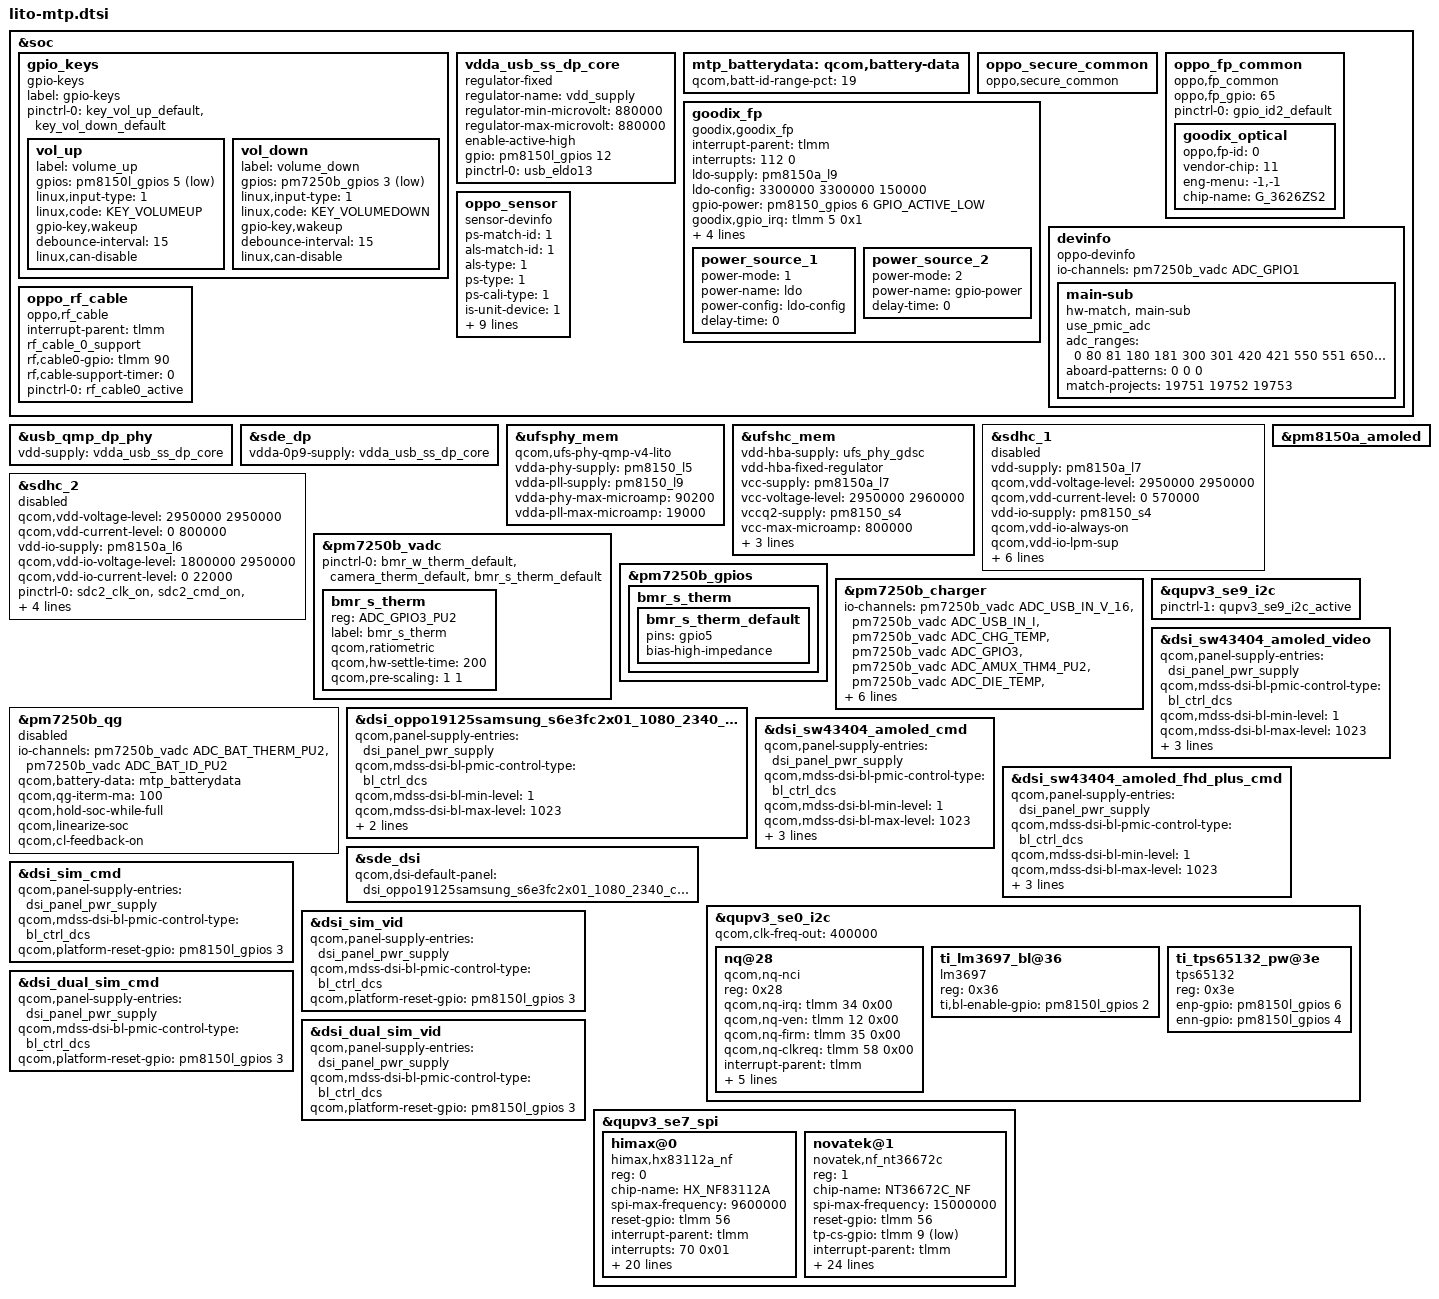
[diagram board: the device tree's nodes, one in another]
#include <dt-bindings/gpio/gpio.h>
#include "lito-audio-overlay.dtsi"
#include "lito-pmic-overlay.dtsi"
#include "camera/lito-camera-sensor-mtp.dtsi"
#include "lito-sde-display.dtsi"
#include "lito-thermal-overlay.dtsi"
#include "oppo_charge.dtsi"

&soc {
	gpio_keys {
		compatible = "gpio-keys";
		label = "gpio-keys";

		pinctrl-names = "default";
		//#ifdef VENDOR_EDIT
		//Fei.Mo@BSP.group 2018-09-01 Modity for vol key
		pinctrl-0 = <&key_vol_up_default &key_vol_down_default>;
		//#endif

		vol_up {
			label = "volume_up";
			gpios = <&pm8150l_gpios 5 GPIO_ACTIVE_LOW>;
			linux,input-type = <1>;
			linux,code = <KEY_VOLUMEUP>;
			gpio-key,wakeup;
			debounce-interval = <15>;
			linux,can-disable;
		};
		//#ifdef VENDOR_EDIT
		//Fei.Mo@BSP.group 2018-09-01 Add for vol key
		vol_down {
			label = "volume_down";
			gpios = <&pm7250b_gpios  3 GPIO_ACTIVE_LOW>;
			linux,input-type = <1>;
			linux,code = <KEY_VOLUMEDOWN>;
			gpio-key,wakeup;
			debounce-interval = <15>;
			linux,can-disable;
		};
		//#endif
	};

	vdda_usb_ss_dp_core: vdda_usb_ss_dp_core {
		compatible = "regulator-fixed";
		regulator-name = "vdd_supply";
		regulator-min-microvolt = <880000>;
		regulator-max-microvolt = <880000>;
		enable-active-high;
		gpio = <&pm8150l_gpios 12 GPIO_ACTIVE_HIGH>;
		pinctrl-names = "default";
		pinctrl-0 = <&usb_eldo13>;
	};

	mtp_batterydata: qcom,battery-data {
//#ifndef VENDOR_EDIT
//Yichun.Chen@BSP.CHG.Basic  2018/05/10  Delete for use oppo battery
//		qcom,batt-id-range-pct = <15>;
//#else
        qcom,batt-id-range-pct = <19>;
//#endif
		#include "qg-batterydata-alium-3600mah.dtsi"
		#include "qg-batterydata-atl466271_3300mAh.dtsi"
	};
	// #ifdef VENDOR_EDIT
	/* Ping.Liu@Bsp.Fingerprint.Secure 2019-10-16 add for secure proc */
	oppo_secure_common {
		compatible = "oppo,secure_common";
	};
	//#endif //VENDOR_EDIT
	//#ifdef VENDOR_EDIT /*VENDOR_EDIT*/
	/*Bangxiong.Wu@BSP.Fingerprint.Basic,2019-04-16 add for fingerprint*/
	oppo_fp_common {
		compatible = "oppo,fp_common";
		oppo,fp_gpio = <65>;
		pinctrl-names = "default";
		pinctrl-0 = <&gpio_id2_default>;
		goodix_optical {
			oppo,fp-id = <0>; /* fp id mapping table */
			vendor-chip = <11>; /* please refer to the struct fp_vendor_t in oppo_fp_commmon.n */
			eng-menu = "-1,-1"; /* represents SNR, inclination test item in engineer menu, and 0/1 means off/on */
			chip-name = "G_3626ZS2";  /* /proc/fp_id, will be displayed in engineer menu  */
		};
	};

	/*Bangxiong.Wu@BSP.Fingerprint.Basic,2019-04-16 add for goodix fingerprint*/
	/*oujinrong@BSP.Fingerprint.Basic,2019-09-02 add for goodix fingerprint multi-power*/
	goodix_fp {
		status = "ok";
		compatible = "goodix,goodix_fp";
		interrupt-parent = <&tlmm>;
		interrupts = <112 0>;

		ldo-supply = <&pm8150a_l9>; // pm660l_l5 for goodix_fp
		ldo-config = <3300000 3300000 150000>;

		gpio-power = <&pm8150_gpios 6 GPIO_ACTIVE_LOW>;
		goodix,gpio_irq = <&tlmm 5 0x1>;
		goodix,gpio_reset = <&tlmm 63 0x0>;
		pinctrl-names = "default";
		pinctrl-0 = <&gpio_goodix_irq_default>;
		pinctrl-1 = <&goodix_pwr_default>;

		power-num = <2> ;
		power_source_1 {
			power-mode = <1>;   /* 1 = ldo power, refer to oppo_fp_common.h*/
			power-name = "ldo";
			power-config = "ldo-config";
			delay-time = <0>;
		};
		power_source_2 {
			power-mode = <2>;   /* 2 = gpio power, refer to oppo_fp_common.h */
			power-name = "gpio-power";
			delay-time = <0>;
		};
	};
	//#endif /*VENDOR_EDIT*/

	/*xing.xiong@BSP.Kernel.Driver, 2019/09/10, Add for adc read for aboard*/
	devinfo {
		compatible = "oppo-devinfo";

		io-channels= <&pm7250b_vadc ADC_GPIO1>;
		io-channel-names= "vph_pwr_voltage_sub";

		main-sub {
			compatible = "hw-match, main-sub";
			use_pmic_adc;
			adc_ranges = <0 80
						81 180
						181 300
						301 420
						421 550
						551 650
						651 760
						761 850
						851 850
						951 1050
						1051 1150
						1151 1300>;
			aboard-patterns = <0 0 0>;

			/*main board*/
			match-projects = <19751 19752 19753>;
		};
	};
	//#ifdef VENDOR_EDIT
	/*Murphy@BSP.sensor, 2019/09/10, Add for sensor dts*/
	oppo_sensor {
		status = "ok";
		compatible = "sensor-devinfo";
		ps-match-id = <1>; //1:STK3A5X;2:TCS3701
		als-match-id = <1>; //1:STK3A5X;2:TCS3701
		als-type = <1>; //NORMAL=1,UNDER_LCD=2,VIRTUAL_UNDER_LCD=3,
		ps-type = <1>; //normal
		ps-cali-type = <1>; //SOFTWARE_CAIL
		is-unit-device = <1>; //two in one device
		is-als-dri = <0>; //0:polling,1:dri
		irq-number = <111>;
		bus-number = <5>;
		als-factor = <2000>;
		ak-msensor-dir = <0>;
		mx-msensor-dir = <0>;
		st-gsensor-dir = <0>;
		bs-gsensor-dir = <0>;
		als-row-coe = <151>;
	};
	//#endif /*VENDOR_EDIT*/

        //#ifdef VENDOR_EDIT
       /* ping.wu@RM.BSP.Basic 2019/11/01 modify for oppo rf cable monitor */
      oppo_rf_cable {
              compatible = "oppo,rf_cable";
              interrupt-parent = <&tlmm>;
              rf_cable_0_support;
              rf,cable0-gpio = <&tlmm 90 0>;
              rf,cable-support-timer = <0>;
              pinctrl-names = "rf_cable_active";
              pinctrl-0 = <&rf_cable0_active>;
      };
     //#endif /* VENDOR_EDIT */
};

//#ifndef VENDOR_EDIT
//Kun.Zhang@BSP.CHG.Basic  2019/09/25  Delete for usb eye parameter
//&usb2_phy0 {
//	qcom,param-override-seq = <0xa1 0x6c
//				0x43 0x70>;
//};
//#endif

&usb_qmp_dp_phy {
	vdd-supply = <&vdda_usb_ss_dp_core>;
};

&sde_dp {
	vdda-0p9-supply = <&vdda_usb_ss_dp_core>;
};

&ufsphy_mem {
	compatible = "qcom,ufs-phy-qmp-v4-lito";

	vdda-phy-supply = <&pm8150_l5>;
	vdda-pll-supply = <&pm8150_l9>;
	vdda-phy-max-microamp = <90200>;
	vdda-pll-max-microamp = <19000>;

	status = "ok";
};

&ufshc_mem {
	vdd-hba-supply = <&ufs_phy_gdsc>;
	vdd-hba-fixed-regulator;
	vcc-supply = <&pm8150a_l7>;
	vcc-voltage-level = <2950000 2960000>;
	vccq2-supply = <&pm8150_s4>;
	vcc-max-microamp = <800000>;
	vccq2-max-microamp = <800000>;

	qcom,vddp-ref-clk-supply = <&pm8150_l9>;
	qcom,vddp-ref-clk-max-microamp = <100>;

	status = "ok";
};

&sdhc_1 {
	vdd-supply = <&pm8150a_l7>;
	qcom,vdd-voltage-level = <2950000 2950000>;
	qcom,vdd-current-level = <0 570000>;

	vdd-io-supply = <&pm8150_s4>;
	qcom,vdd-io-always-on;
	qcom,vdd-io-lpm-sup;
	qcom,vdd-io-voltage-level = <1800000 1800000>;
	qcom,vdd-io-current-level = <0 325000>;

	pinctrl-names = "active", "sleep";
	pinctrl-0 = <&sdc1_clk_on &sdc1_cmd_on &sdc1_data_on
					&sdc1_rclk_on>;
	pinctrl-1 = <&sdc1_clk_off &sdc1_cmd_off &sdc1_data_off
					&sdc1_rclk_off>;
//#ifndef VENDOR_EDIT
//yh@PSW.BSP.Storage.UFS, 2018-06-04 add for disable sdhci
//	status = "ok";
//#else
	status = "disabled";
//#endif
};

&sdhc_2 {
/* #ifndef VENDOR_EDIT */
/* oujinrong@BSP.Fingerprint.Basic 2019/08/27, remove for fingerprint power */
/* vdd-supply = <&pm8150a_l9>;*/
/* #endif VENDOR_EDIT */
	qcom,vdd-voltage-level = <2950000 2950000>;
	qcom,vdd-current-level = <0 800000>;

	vdd-io-supply = <&pm8150a_l6>;
	qcom,vdd-io-voltage-level = <1800000 2950000>;
	qcom,vdd-io-current-level = <0 22000>;

	pinctrl-names = "active", "sleep";
	pinctrl-0 = <&sdc2_clk_on  &sdc2_cmd_on &sdc2_data_on &sdc2_cd_on>;
	pinctrl-1 = <&sdc2_clk_off &sdc2_cmd_off &sdc2_data_off &sdc2_cd_off>;

	cd-gpios = <&tlmm 69 GPIO_ACTIVE_LOW>;
//#ifndef VENDOR_EDIT
//yh@PSW.BSP.Storage.UFS, 2018-06-04 add for disable sdhci
//	status = "ok";
//#else
	status = "disabled";
//#endif
};

&pm8150a_amoled {
	status = "ok";
};

&pm7250b_vadc {
	pinctrl-0 = <
		&bmr_w_therm_default
		&camera_therm_default
		&bmr_s_therm_default
	>;

	bmr_s_therm {
		reg = <ADC_GPIO3_PU2>;
		label = "bmr_s_therm";
		qcom,ratiometric;
		qcom,hw-settle-time = <200>;
		qcom,pre-scaling = <1 1>;
	};
};

&pm7250b_gpios {
	bmr_s_therm {
		bmr_s_therm_default: bmr_s_therm_default {
			pins = "gpio5";
			bias-high-impedance;
		};
	};
};

&pm7250b_charger {
	status = "ok";
	io-channels = <&pm7250b_vadc ADC_USB_IN_V_16>,
		      <&pm7250b_vadc ADC_USB_IN_I>,
		      <&pm7250b_vadc ADC_CHG_TEMP>,
//#ifdef VENDOR_EDIT /* tongfeng.Huang@BSP.CHG.Basic, 2016/12/26,  Add for charging chgID */
			  <&pm7250b_vadc ADC_GPIO3>,
			  <&pm7250b_vadc ADC_AMUX_THM4_PU2>,
//#endif
		      <&pm7250b_vadc ADC_DIE_TEMP>,
		      <&pm7250b_vadc ADC_AMUX_THM3_PU2>,
		      <&pm7250b_vadc ADC_SBUx>,
		      <&pm7250b_vadc ADC_VPH_PWR>;
	io-channel-names = "usb_in_voltage",
			   "usb_in_current",
			   "chg_temp",
//#ifdef VENDOR_EDIT /* Kun.Zhang@BSP.CHG.Basic, 2019/09/18,  Add for charging chgID */
			   "chgID_voltage_adc",
			   "usb_temp_l",
//#endif
			   "die_temp",
//#ifdef VENDOR_EDIT /* Kun.Zhang@BSP.CHG.Basic, 2019/09/18,  Add for charging usbtemp */
			   "usb_temp_r",
//#else
			   //"conn_temp",
//#endif
			   "sbux_res",
			   "vph_voltage";
	qcom,battery-data = <&mtp_batterydata>;
//#ifdef VENDOR_EDIT /* Kun.Zhang@BSP.CHG.Basic, 2019/09/18,  Remove for charging */
	//qcom,sec-charger-config = <1>;
	//qcom,auto-recharge-soc = <98>;
	//qcom,step-charging-enable;
	//qcom,sw-jeita-enable;
//#endif
	qcom,charger-temp-max = <800>;
	qcom,smb-temp-max = <800>;
//#ifdef VENDOR_EDIT /* Kun.Zhang@BSP.CHG.Basic, 2019/09/18,  Remove for charging */
	//qcom,suspend-input-on-debug-batt;
	//qcom,fcc-stepping-enable;
//#endif
};

&pm7250b_qg {
//#ifdef VENDOR_EDIT /* Kun.Zhang@BSP.CHG.Basic, 2019/09/18,  Remove for charging */
	status = "disabled";
//#else
	//status = "ok";
//#endif
	io-channels = <&pm7250b_vadc ADC_BAT_THERM_PU2>,
		      <&pm7250b_vadc ADC_BAT_ID_PU2>;
	io-channel-names = "batt-therm",
			   "batt-id";
	qcom,battery-data = <&mtp_batterydata>;
	qcom,qg-iterm-ma = <100>;
	qcom,hold-soc-while-full;
	qcom,linearize-soc;
	qcom,cl-feedback-on;
};

//&qupv3_se7_i2c {
//	#address-cells = <1>;
//	#size-cells = <0>;

//	status = "ok";
//	qcom,i2c-touch-active = "st,fts";
/*
	st_fts@49 {
		compatible = "st,fts";
		reg = <0x49>;
		interrupt-parent = <&tlmm>;
		//interrupts = <9 0x2008>;
		vdd-supply = <&pm8150_s4>;
		avdd-supply = <&pm8150_l13>;
		pinctrl-names = "pmx_ts_active", "pmx_ts_suspend";
		pinctrl-0 = <&ts_active>;
		pinctrl-1 = <&ts_int_suspend &ts_reset_suspend>;
		//st,irq-gpio = <&tlmm 9 0x2008>;
		//st,reset-gpio = <&tlmm 8 0x00>;
		st,regulator_dvdd = "vdd";
		st,regulator_avdd = "avdd";
		st,x-flip = <1>;
		st,y-flip = <1>;
		st,power_on_suspend;
		panel = <&dsi_sw43404_amoled_cmd &dsi_sw43404_amoled_video
			 &dsi_sw43404_amoled_fhd_plus_cmd>;
	};
*/
	//#ifdef VENDOR_EDIT
	//wangkun@BSP.group 2019-06-28 add for enable i2c_7
	//synaptics19007@20 {
	//	compatible = "synaptics-s3706";
	//	reg = <0x20>;
	//	chip-name = "S3706";

		/* Interrupt && Irq-gpio */
	//	interrupt-parent = <&tlmm>;
		//interrupts = <9 0x2008>;

		/* Power Config */
	//	vdd_2v8-supply = <&pm8150_l13>;
	//	vcc_1v8-supply = <&pm8150a_l1>;
	//	vdd_2v8_volt = <3000000>;

		/* Other HW Resource */
		//irq-gpio = <&tlmm 9 0x2008>;
		//reset-gpio = <&tlmm 8 0x1>;
	//	pinctrl-names = "default";
	//	pinctrl-0 = <&ts_int_active &ts_reset_active>;

	//	touchpanel,max-num-support = <10>;
	//	touchpanel,tx-rx-num = <16 34>;
	//	touchpanel,panel-coords = <1080 2340>;
	//	touchpanel,display-coords = <1080 2340>;
	//	touchpanel,touchmajor-limit = <0 54>;

		/* SW Support Feature Control */
	//	black_gesture_support;
	//	fw_edge_limit_support;
	//	fw_corner_limit_support;
	//	pressure_report_support;
	//	//spurious_fingerprint_support;
	//	charger_pump_support;
	//	game_switch_support;
	//	face_detect_support;
	//	smart_gesture_support;
	//	fw_update_app_support;
	//	fingerprint_underscreen_support;
	//	rt155_fdreplace_rt59_support;
	//	report_120hz_support;
		/*
		 *Virtual Key Config:
		 *1:touchpanel,button-type: <virtualkey_type  supportted_button-map>
		 *virtualkey_type:
		 *Type 1: using board_properties
		 *Type 2: using same IC (button zone&& touch zone are seprate)
		 *Type 3: using diffrent IC (button zone&& touch zone are seprate)
		 *Type 4: No need of virtual key process
		 *supportted_button-map:select|menu|home|back
		 *
		 *2:touchpanel,button-map
		 *type (X1,Y1)(X2,Y2)(X3,Y3)(Width_X,Hight_Y)--Only when button-type is 0
		 */
	//	touchpanel,button-type = <4>;
	//	touchpanel.button-TRx = <0 0>;
	//};
	//#endif

	//#ifdef VENDOR_EDIT
	//Zengpeng.Chen@BSP.TP.Function 2019-08-25 add for enable Goodix touch device
	//Goodix19125@5d {
	//	compatible = "Goodix-gt9886";
	//	reg = <0x5d>;
	//	chip-name = "gt9886";

		/* Interrupt && Irq-gpio */
	//	interrupt-parent = <&tlmm>;
		//interrupts = <9 0x2008>;

		/* Power Config */
	//	vdd_2v8-supply = <&pm8150_l13>;
	//	vcc_1v8-supply = <&pm8150a_l1>;
	//	vdd_2v8_volt = <3000000>;

		/* Other HW Resource */
		//irq-gpio = <&tlmm 9 0x2008>;
		//reset-gpio = <&tlmm 8 0x1>;
	//	pinctrl-names = "default";
	//	pinctrl-0 = <&ts_int_active &ts_reset_active>;

	//	touchpanel,max-num-support = <10>;
	//	touchpanel,tx-rx-num = <15 34>;
	//	touchpanel,panel-coords = <1080 2400>;
	//	touchpanel,display-coords = <1080 2400>;
	//	touchpanel,touchmajor-limit = <0 54>;

		/* SW Support Feature Control */
	//	register-is-16bit;
	//	black_gesture_support;
	//	fw_edge_limit_support;
	//	pressure_report_support;
		//spurious_fingerprint_support;
	//	charger_pump_support;
	//	game_switch_support;
		//face_detect_support;
	//	smart_gesture_support;
		//fw_update_app_support;
		//fingerprint_underscreen_support;
		/*
		 *Virtual Key Config:
		 *1:touchpanel,button-type: <virtualkey_type  supportted_button-map>
		 *virtualkey_type:
		 *Type 1: using board_properties
		 *Type 2: using same IC (button zone&& touch zone are seprate)
		 *Type 3: using diffrent IC (button zone&& touch zone are seprate)
		 *Type 4: No need of virtual key process
		 *supportted_button-map:select|menu|home|back
		 *
		 *2:touchpanel,button-map
		 *type (X1,Y1)(X2,Y2)(X3,Y3)(Width_X,Hight_Y)--Only when button-type is 0
		 */
	//	touchpanel,button-type = <4>;
	//	touchpanel.button-TRx = <0 0>;
	//};
	//#endif
//};

&qupv3_se9_i2c {
	/* Override sleep state of pins */
	pinctrl-1 = <&qupv3_se9_i2c_active>;
};

//#ifdef VENDOR_EDIT
/*
 * Ling.Guo@PSW.MM.Display.LCD.Stability, 2019/06/28,
 * add for 19125 samsung amoled
 */
&dsi_oppo19125samsung_s6e3fc2x01_1080_2340_cmd {
	qcom,panel-supply-entries = <&dsi_panel_pwr_supply>;
	qcom,mdss-dsi-bl-pmic-control-type = "bl_ctrl_dcs";
	qcom,mdss-dsi-bl-min-level = <1>;
	qcom,mdss-dsi-bl-max-level = <1023>;
	qcom,platform-te-gpio = <&tlmm 10 0>;
	qcom,platform-reset-gpio = <&pm8150l_gpios 3 0>;
};
//#endif /*VENDOR_EDIT*/

&dsi_sw43404_amoled_video {
	qcom,panel-supply-entries = <&dsi_panel_pwr_supply>;
	qcom,mdss-dsi-bl-pmic-control-type = "bl_ctrl_dcs";
	qcom,mdss-dsi-bl-min-level = <1>;
	qcom,mdss-dsi-bl-max-level = <1023>;
	qcom,mdss-brightness-max-level = <255>;
	qcom,platform-te-gpio = <&tlmm 10 0>;
	qcom,platform-reset-gpio = <&pm8150l_gpios 3 0>;
};

&dsi_sw43404_amoled_cmd {
	qcom,panel-supply-entries = <&dsi_panel_pwr_supply>;
	qcom,mdss-dsi-bl-pmic-control-type = "bl_ctrl_dcs";
	qcom,mdss-dsi-bl-min-level = <1>;
	qcom,mdss-dsi-bl-max-level = <1023>;
	qcom,mdss-brightness-max-level = <255>;
	qcom,platform-te-gpio = <&tlmm 10 0>;
	qcom,platform-reset-gpio = <&pm8150l_gpios 3 0>;
};

&dsi_sw43404_amoled_fhd_plus_cmd {
	qcom,panel-supply-entries = <&dsi_panel_pwr_supply>;
	qcom,mdss-dsi-bl-pmic-control-type = "bl_ctrl_dcs";
	qcom,mdss-dsi-bl-min-level = <1>;
	qcom,mdss-dsi-bl-max-level = <1023>;
	qcom,mdss-brightness-max-level = <255>;
	qcom,platform-te-gpio = <&tlmm 10 0>;
	qcom,platform-reset-gpio = <&pm8150l_gpios 3 0>;
};

&sde_dsi {
	qcom,dsi-default-panel = <&dsi_oppo19125samsung_s6e3fc2x01_1080_2340_cmd>;
};

&qupv3_se0_i2c {
//#ifdef VENDOR_EDIT
// zhangyuwei@MM.Display.LCD.Machine 2019-10-14
	status = "ok";
	qcom,clk-freq-out = <400000>;
//#else
//	status = "disabled";
//	qcom,clk-freq-out = <1000000>;
//#endif
	#address-cells = <1>;
	#size-cells = <0>;
	nq@28 {
		compatible = "qcom,nq-nci";
		reg = <0x28>;
		qcom,nq-irq = <&tlmm 34 0x00>;
		qcom,nq-ven = <&tlmm 12 0x00>;
		qcom,nq-firm = <&tlmm 35 0x00>;
		qcom,nq-clkreq = <&tlmm 58 0x00>;
		interrupt-parent = <&tlmm>;
		interrupts = <34 0>;
		interrupt-names = "nfc_irq";
		pinctrl-names = "nfc_active", "nfc_suspend";
		pinctrl-0 = <&nfc_int_active &nfc_enable_active
				&nfc_clk_req_active>;
		pinctrl-1 = <&nfc_int_suspend &nfc_enable_suspend
				&nfc_clk_req_suspend>;
	};

//#ifdef VENDOR_EDIT
// zhangyuwei@MM.Display.LCD.Machine 2019-10-14 add nodes for backlight and lcd power
    ti_lm3697_bl@36 {
	    compatible = "lm3697";
        reg = <0x36>;
        ti,bl-enable-gpio = <&pm8150l_gpios 2 0>;
    };

    ti_tps65132_pw@3e {
        compatible = "tps65132";
        reg = <0x3e>;
        status = "okay";
        enp-gpio = <&pm8150l_gpios 6 0>;
        enn-gpio = <&pm8150l_gpios 4 0>;
    };
//#endif
};

&dsi_sim_cmd {
	qcom,panel-supply-entries = <&dsi_panel_pwr_supply>;
	qcom,mdss-dsi-bl-pmic-control-type = "bl_ctrl_dcs";
	qcom,platform-reset-gpio = <&pm8150l_gpios 3 0>;
};

&dsi_sim_vid {
	qcom,panel-supply-entries = <&dsi_panel_pwr_supply>;
	qcom,mdss-dsi-bl-pmic-control-type = "bl_ctrl_dcs";
	qcom,platform-reset-gpio = <&pm8150l_gpios 3 0>;
};

&dsi_dual_sim_cmd {
	qcom,panel-supply-entries = <&dsi_panel_pwr_supply>;
	qcom,mdss-dsi-bl-pmic-control-type = "bl_ctrl_dcs";
	qcom,platform-reset-gpio = <&pm8150l_gpios 3 0>;
};

&dsi_dual_sim_vid {
	qcom,panel-supply-entries = <&dsi_panel_pwr_supply>;
	qcom,mdss-dsi-bl-pmic-control-type = "bl_ctrl_dcs";
	qcom,platform-reset-gpio = <&pm8150l_gpios 3 0>;
};
/*Wenping.ZHOU@BSP.TP.Function, 2019/09/20, add for Himax noflash TP*/
&qupv3_se7_spi {
	/* Himax device tree node */
	status = "ok";
	#address-cells = <1>;
	#size-cells = <0>;
	himax@0 {
		compatible = "himax,hx83112a_nf";
		reg = <0>;
		chip-name = "HX_NF83112A";
		status = "okay";

		spi-max-frequency = <9600000>;	//4800000,9600000,15000000,19200000
		reset-gpio = <&tlmm 56 0x00>;
		interrupt-parent = <&tlmm>;
		interrupts = <70 0x01>;
		irq-gpio = <&tlmm 70 0x2001>;
		/*lcd-reset-gpio = <&tlmm 26 0x00>;*/
		pinctrl-names = "default";
		pinctrl-0 = <&ts_int_active &ts_reset_active>;

		touchpanel,max-num-support = <10>;
		touchpanel,tx-rx-num = <16 36>;
		touchpanel,panel-coords = <1080 2340>;
		touchpanel,display-coords = <1080 2340>;

		incell_screen;
		fw_edge_limit_support;
		black_gesture_support;
		charger_pump_support;
		headset_pump_support;
		//spurious_fingerprint_support;
		//lcd_trigger_fp_check;
		esd_handle_support;
		black_gesture_test_support;
		game_switch_support;
		noflash_support;
		lcd_trigger_load_tp_fw_support;
		smart_gesture_support;
		pressure_report_support;
		fw_update_app_support;

		/*
		*Virtual Key Config:
		*1:touchpanel,button-type: <virtualkey_type  supportted_button-map>
		*virtualkey_type:
		*Type 1: using board_properties
		*Type 2: using same IC (button zone&& touch zone are seprate)
		*Type 3: using diffrent IC (button zone&& touch zone are seprate)
		*Type 4: No need of virtual key process
		*supportted_button-map:select|menu|home|back
		*
		*2:touchpanel,button-map
		*type (X1,Y1)(X2,Y2)(X3,Y3)(Width_X,Hight_Y)--Only when button-type is 0
		*/

		touchpanel,button-type = <4>;
	};
/*Wenping.ZHOU@BSP.TP.Function, 2019/09/20, add for novatek noflash TP*/
	novatek@1 {
		compatible = "novatek,nf_nt36672c";
		reg = <1>;
		chip-name = "NT36672C_NF";
		status = "ok";

		//spi-max-frequency = <9600000>;	//4800000,9600000,15000000,19200000
		spi-max-frequency = <15000000>; //4800000,9600000,15000000,19200000
		reset-gpio = <&tlmm 56 0x00>;
		tp-cs-gpio = <&tlmm 9 0x01>;
		interrupt-parent = <&tlmm>;
		interrupts = <70 0x0>;
		irq-gpio = <&tlmm 70 0x2002>;
                //lcd-reset-gpio = <&pm8150l_gpios 3 0>;
		touchpanel,tx-rx-num = <18 36>;
		touchpanel,max-num-support = <10>;
		touchpanel,panel-coords = <1080 2400>;
		touchpanel,display-coords = <1080 2400>;
		touchpanel,touchmajor-limit = <0 54>;
		
		pinctrl-names = "default", "suspend";
		pinctrl-0 = <&ts_int_active &ts_reset_active>;
		pinctrl-1 = <&ts_int_suspend &ts_reset_suspend>;

		incell_screen;
		fw_edge_limit_support;
		black_gesture_support;
		charger_pump_support;
		headset_pump_support;
		//spurious_fingerprint_support;
		//lcd_trigger_fp_check;
		esd_handle_support;
		black_gesture_test_support;
		game_switch_support;
		noflash_support;
		lcd_trigger_load_tp_fw_support;
		smart_gesture_support;
		new_set_irq_wake_support;
		pressure_report_support;
		fw_update_app_support;
		touchpanel,button-type = <4>;

	};
};
